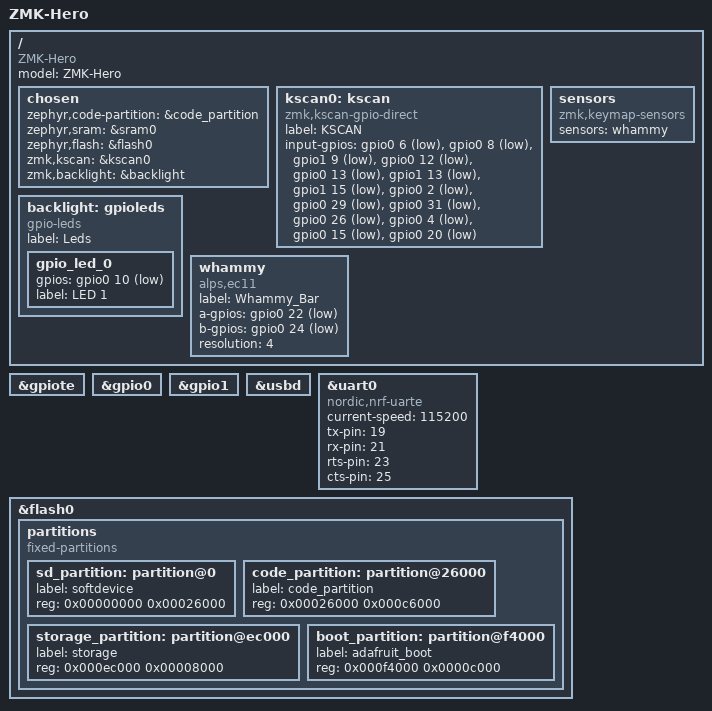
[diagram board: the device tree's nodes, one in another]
/dts-v1/;
#include <nordic/nrf52840_qiaa.dtsi>

#include <dt-bindings/led/led.h>
#include <dt-bindings/zmk/matrix_transform.h>

/ {
	model = "ZMK-Hero";
	compatible = "ZMK-Hero";

	chosen {
		zephyr,code-partition = &code_partition;
		zephyr,sram = &sram0;
		zephyr,flash = &flash0;
		zmk,kscan = &kscan0;
        zmk,backlight = &backlight;
	};
    

	kscan0: kscan {
		compatible = "zmk,kscan-gpio-direct";

		label = "KSCAN";

		input-gpios
            = <&gpio0 6 (GPIO_ACTIVE_LOW | GPIO_PULL_UP)>
            , <&gpio0 8 (GPIO_ACTIVE_LOW | GPIO_PULL_UP)>
            , <&gpio1 9 (GPIO_ACTIVE_LOW | GPIO_PULL_UP)>
            , <&gpio0 12 (GPIO_ACTIVE_LOW | GPIO_PULL_UP)>
            , <&gpio0 13 (GPIO_ACTIVE_LOW | GPIO_PULL_UP)>
			, <&gpio1 13 (GPIO_ACTIVE_LOW | GPIO_PULL_UP)>
			, <&gpio1 15 (GPIO_ACTIVE_LOW | GPIO_PULL_UP)>
            , <&gpio0 2 (GPIO_ACTIVE_LOW | GPIO_PULL_UP)>
            , <&gpio0 29 (GPIO_ACTIVE_LOW | GPIO_PULL_UP)>
            , <&gpio0 31 (GPIO_ACTIVE_LOW | GPIO_PULL_UP)>
            , <&gpio0 26 (GPIO_ACTIVE_LOW | GPIO_PULL_UP)>
            , <&gpio0 4 (GPIO_ACTIVE_LOW | GPIO_PULL_UP)>
            , <&gpio0 15 (GPIO_ACTIVE_LOW | GPIO_PULL_UP)>
            , <&gpio0 20 (GPIO_ACTIVE_LOW | GPIO_PULL_UP)>
			;
	};
	
    
    backlight: gpioleds {
        compatible = "gpio-leds";
        label = "Leds";
        gpio_led_0 {
            gpios = <&gpio0 10 GPIO_ACTIVE_LOW>;
            label = "LED 1";
        };
    };
    
    whammy: whammy {
        compatible = "alps,ec11";
        label = "Whammy_Bar";
        a-gpios = <&gpio0 22 (GPIO_ACTIVE_LOW | GPIO_PULL_UP)>;
        b-gpios = <&gpio0 24 (GPIO_ACTIVE_LOW | GPIO_PULL_UP)>;
        resolution = <4>;
        status = "okay";
    };
    
    sensors {
        compatible = "zmk,keymap-sensors";
        sensors = <&whammy>;
    };
    
};

&gpiote {
	status = "okay";
};

&gpio0 {
	status = "okay";
};

&gpio1 {
	status = "okay";
};

&usbd {
	status = "okay";
};

&uart0 {
	compatible = "nordic,nrf-uarte";
	status = "okay";
	current-speed = <115200>;
	tx-pin = <19>;
	rx-pin = <21>;
	rts-pin = <23>;
	cts-pin = <25>;
};


&flash0 {
	/*
	 * For more information, see:
	 * http://docs.zephyrproject.org/latest/devices/dts/flash_partitions.html
	 */
	partitions {
		compatible = "fixed-partitions";
		#address-cells = <1>;
		#size-cells = <1>;

		sd_partition: partition@0 {
			label = "softdevice";
			reg = <0x00000000 0x00026000>;
		};
		code_partition: partition@26000 {
			label = "code_partition";
			reg = <0x00026000 0x000c6000>;
		};

		/*
		 * The flash starting at 0x000ec000 and ending at
		 * 0x000f3fff is reserved for use by the application.
		 */

		/*
		 * Storage partition will be used by FCB/LittleFS/NVS
		 * if enabled.
		 */
		storage_partition: partition@ec000 {
			label = "storage";
			reg = <0x000ec000 0x00008000>;
		};

		boot_partition: partition@f4000 {
			label = "adafruit_boot";
			reg = <0x000f4000 0x0000c000>;
		};
	};
};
